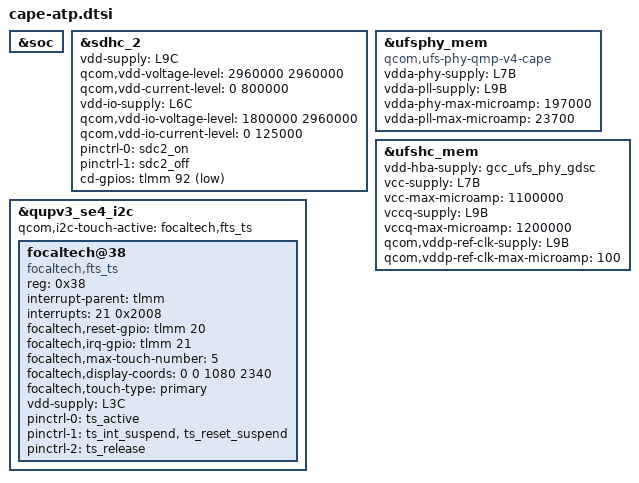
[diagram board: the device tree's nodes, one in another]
#include "cape-pmic-overlay.dtsi"
#include <dt-bindings/gpio/gpio.h>

&soc { };

&sdhc_2 {
	status = "ok";
	vdd-supply = <&L9C>;
	qcom,vdd-voltage-level = <2960000 2960000>;
	qcom,vdd-current-level = <0 800000>;

	vdd-io-supply = <&L6C>;
	qcom,vdd-io-voltage-level = <1800000 2960000>;
	qcom,vdd-io-current-level = <0 125000>;

	pinctrl-names = "default", "sleep";
	pinctrl-0 = <&sdc2_on>;
	pinctrl-1 = <&sdc2_off>;

	cd-gpios = <&tlmm 92 GPIO_ACTIVE_LOW>;
};

&ufsphy_mem {
	compatible = "qcom,ufs-phy-qmp-v4-cape";

	vdda-phy-supply = <&L7B>;
	vdda-pll-supply = <&L9B>;
	vdda-phy-max-microamp = <197000>;
	vdda-pll-max-microamp = <23700>;

	status = "ok";
};

&ufshc_mem {
	vdd-hba-supply = <&gcc_ufs_phy_gdsc>;

	vcc-supply = <&L7B>;
	vcc-max-microamp = <1100000>;

	vccq-supply = <&L9B>;
	vccq-max-microamp = <1200000>;

	qcom,vddp-ref-clk-supply = <&L9B>;
	qcom,vddp-ref-clk-max-microamp = <100>;

	status = "ok";
};

&qupv3_se4_i2c {
	#address-cells = <1>;
	#size-cells = <0>;

	status = "ok";
	qcom,i2c-touch-active = "focaltech,fts_ts";

	focaltech@38 {
		compatible = "focaltech,fts_ts";
		reg = <0x38>;
		interrupt-parent = <&tlmm>;
		interrupts = <21 0x2008>;
		focaltech,reset-gpio = <&tlmm 20 0x00>;
		focaltech,irq-gpio = <&tlmm 21 0x2008>;
		focaltech,max-touch-number = <5>;
		focaltech,display-coords = <0 0 1080 2340>;
		focaltech,touch-type = "primary";

		vdd-supply = <&L3C>;

		pinctrl-names = "pmx_ts_active", "pmx_ts_suspend","pmx_ts_release";
		pinctrl-0 = <&ts_active>;
		pinctrl-1 = <&ts_int_suspend &ts_reset_suspend>;
		pinctrl-2 = <&ts_release>;
	};
};
